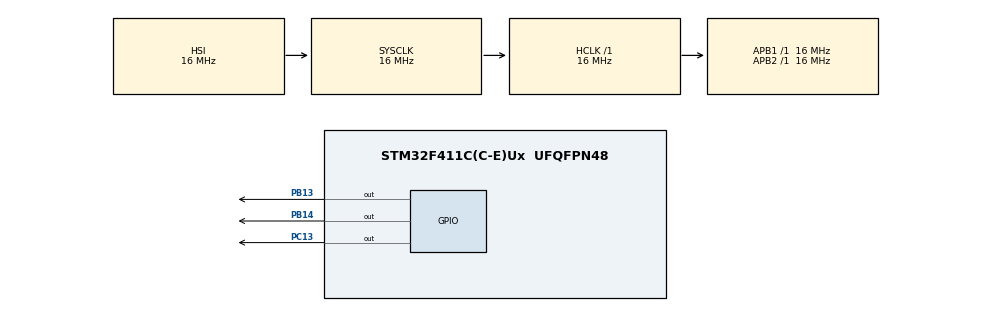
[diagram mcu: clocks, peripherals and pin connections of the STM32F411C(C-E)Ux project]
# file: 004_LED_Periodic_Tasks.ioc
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Mcu.Family=STM32F4
Mcu.Name=STM32F411C(C-E)Ux
Mcu.Package=UFQFPN48
NVIC.PriorityGroup=NVIC_PRIORITYGROUP_4
NVIC.TIM2_IRQn=true\:15\:0\:false\:false\:true\:false\:true\:true
NVIC.TimeBase=TIM2_IRQn
NVIC.TimeBaseIP=TIM2
PB13.Signal=GPIO_Output
PB14.Signal=GPIO_Output
PC13-ANTI_TAMP.Signal=GPIO_Output
ProjectManager.HeapSize=0x200
ProjectManager.StackSize=0x400
ProjectManager.TargetToolchain=STM32CubeIDE
RCC.AHBFreq_Value=16000000
RCC.APB1Freq_Value=16000000
RCC.APB2Freq_Value=16000000
RCC.CortexFreq_Value=16000000
RCC.HSE_VALUE=25000000
RCC.HSI_VALUE=16000000
RCC.LSE_VALUE=32768
RCC.SYSCLKFreq_VALUE=16000000
RCC.VCOOutputFreq_Value=192000000
VP_SYS_VS_tim2.Mode=TIM2
board=custom

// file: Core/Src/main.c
/* USER CODE BEGIN Header */
/**
  ******************************************************************************
  * @file           : main.c
  * @brief          : Main program body
  ******************************************************************************
  * @attention
  *
  * Copyright (c) 2025 STMicroelectronics.
  * All rights reserved.
  *
  * This software is licensed under terms that can be found in the LICENSE file
  * in the root directory of this software component.
  * If no LICENSE file comes with this software, it is provided AS-IS.
  *
  ******************************************************************************
  */
/* USER CODE END Header */
#include "main.h"

/* USER CODE BEGIN Includes */
#include <stdio.h>
#include "FreeRTOS.h"
#include "task.h"

/* USER CODE END Includes */

/* USER CODE BEGIN PV */
#define DWT_CTRL   ( *(volatile uint32_t*) 0xE0001000 )

/* USER CODE END PV */

void SystemClock_Config(void);
static void MX_GPIO_Init(void);
/* USER CODE BEGIN PFP */
static void led1_handler(void* parameters);
static void led2_handler(void* parameters);
static void led3_handler(void* parameters);

/* USER CODE END PFP */

int main(void)
{

  /* USER CODE BEGIN 1 */
	TaskHandle_t task1_handler,task2_handler, task3_handler;
	BaseType_t status;

  /* USER CODE END 1 */

  /* MCU Configuration--------------------------------------------------------*/

  /* Reset of all peripherals, Initializes the Flash interface and the Systick. */
  HAL_Init();

  /* Configure the system clock */
  SystemClock_Config();

  /* Initialize all configured peripherals */
  MX_GPIO_Init();
  /* USER CODE BEGIN 2 */
  //enable the cycle count//
  DWT_CTRL |= (1 << 0);

//  SEGGER_UART_init(50000);

  //calling the APIs to start recording
  SEGGER_SYSVIEW_Conf();
  SEGGER_SYSVIEW_Start();

  status = xTaskCreate(led1_handler, "Task-1", configMINIMAL_STACK_SIZE * 2, "Executing task-1", 2, &task1_handler);
  configASSERT(status == pdPASS);

  status = xTaskCreate(led2_handler, "Task-2", configMINIMAL_STACK_SIZE * 2, "Executing task-2", 2, &task2_handler);
  configASSERT(status == pdPASS);

  status = xTaskCreate(led3_handler, "Task-3", configMINIMAL_STACK_SIZE * 2, "Executing task-3", 2, &task3_handler);
  configASSERT(status == pdPASS);

  //Starting the FreeRTOS Scheduler//
  vTaskStartScheduler();
  //if the control comes here then the launch of the scheduler has failed due to insufficient
  //memory in heap

  /* USER CODE END 2 */

  /* Infinite loop */
  while (1)
  {

  }
}

void SystemClock_Config(void)
{
  RCC_OscInitTypeDef RCC_OscInitStruct = {0};
  RCC_ClkInitTypeDef RCC_ClkInitStruct = {0};

  /** Configure the main internal regulator output voltage
  */
  __HAL_RCC_PWR_CLK_ENABLE();
  __HAL_PWR_VOLTAGESCALING_CONFIG(PWR_REGULATOR_VOLTAGE_SCALE1);

  /** Initializes the RCC Oscillators according to the specified parameters
  * in the RCC_OscInitTypeDef structure.
  */
  RCC_OscInitStruct.OscillatorType = RCC_OSCILLATORTYPE_HSI;
  RCC_OscInitStruct.HSIState = RCC_HSI_ON;
  RCC_OscInitStruct.HSICalibrationValue = RCC_HSICALIBRATION_DEFAULT;
  RCC_OscInitStruct.PLL.PLLState = RCC_PLL_NONE;
  if (HAL_RCC_OscConfig(&RCC_OscInitStruct) != HAL_OK)
  {
    Error_Handler();
  }

  /** Initializes the CPU, AHB and APB buses clocks
  */
  RCC_ClkInitStruct.ClockType = RCC_CLOCKTYPE_HCLK|RCC_CLOCKTYPE_SYSCLK
                              |RCC_CLOCKTYPE_PCLK1|RCC_CLOCKTYPE_PCLK2;
  RCC_ClkInitStruct.SYSCLKSource = RCC_SYSCLKSOURCE_HSI;
  RCC_ClkInitStruct.AHBCLKDivider = RCC_SYSCLK_DIV1;
  RCC_ClkInitStruct.APB1CLKDivider = RCC_HCLK_DIV1;
  RCC_ClkInitStruct.APB2CLKDivider = RCC_HCLK_DIV1;

  if (HAL_RCC_ClockConfig(&RCC_ClkInitStruct, FLASH_LATENCY_0) != HAL_OK)
  {
    Error_Handler();
  }
}

static void MX_GPIO_Init(void)
{
  GPIO_InitTypeDef GPIO_InitStruct = {0};

  /* GPIO Ports Clock Enable */
  __HAL_RCC_GPIOC_CLK_ENABLE();
  __HAL_RCC_GPIOB_CLK_ENABLE();

  /*Configure GPIO pin Output Level */
  HAL_GPIO_WritePin(GPIOC, GPIO_PIN_13, GPIO_PIN_RESET);

  /*Configure GPIO pin Output Level */
  HAL_GPIO_WritePin(GPIOB, GPIO_PIN_13|GPIO_PIN_14, GPIO_PIN_RESET);

  /*Configure GPIO pin : PC13 */
  GPIO_InitStruct.Pin = GPIO_PIN_13;
  GPIO_InitStruct.Mode = GPIO_MODE_OUTPUT_PP;
  GPIO_InitStruct.Pull = GPIO_NOPULL;
  GPIO_InitStruct.Speed = GPIO_SPEED_FREQ_LOW;
  HAL_GPIO_Init(GPIOC, &GPIO_InitStruct);

  /*Configure GPIO pins : PB13 PB14 */
  GPIO_InitStruct.Pin = GPIO_PIN_13|GPIO_PIN_14;
  GPIO_InitStruct.Mode = GPIO_MODE_OUTPUT_PP;
  GPIO_InitStruct.Pull = GPIO_NOPULL;
  GPIO_InitStruct.Speed = GPIO_SPEED_FREQ_LOW;
  HAL_GPIO_Init(GPIOB, &GPIO_InitStruct);

}

/* USER CODE BEGIN 4 */
static void led1_handler(void* parameters)
{
	TickType_t prev_waketime = xTaskGetTickCount();
	while(1)
	{
		SEGGER_SYSVIEW_PrintfTarget("Toggling blue LED");
		HAL_GPIO_TogglePin(GPIOC, GPIO_PIN_13);
		vTaskDelayUntil(&prev_waketime, pdMS_TO_TICKS(1000));
//		taskYIELD();
	}
}
static void led2_handler(void* parameters)
{
	TickType_t prev_waketime = xTaskGetTickCount();
	while(1)
	{
		SEGGER_SYSVIEW_PrintfTarget("Toggling B13 Pin");
		HAL_GPIO_TogglePin(GPIOB, GPIO_PIN_13);
		vTaskDelayUntil(&prev_waketime, pdMS_TO_TICKS(800));
//		taskYIELD();
	}
}
static void led3_handler(void* parameters)
{
	TickType_t prev_waketime = xTaskGetTickCount();
	while(1)
	{
		SEGGER_SYSVIEW_PrintfTarget("Toggling B14 Pin");
		HAL_GPIO_TogglePin(GPIOB, GPIO_PIN_14);
		vTaskDelayUntil(&prev_waketime, pdMS_TO_TICKS(400));
//		taskYIELD();
	}
}

/* USER CODE END 4 */

void HAL_TIM_PeriodElapsedCallback(TIM_HandleTypeDef *htim)
{
  if (htim->Instance == TIM2)
  {
    HAL_IncTick();
  }
}

void Error_Handler(void)
{
  __disable_irq();
  while (1)
  {
  }
}
